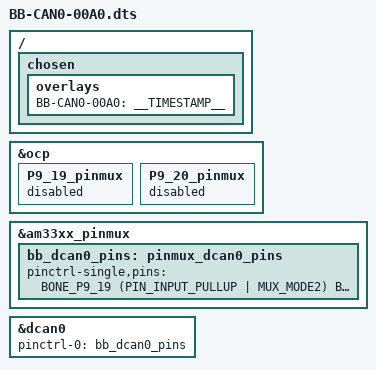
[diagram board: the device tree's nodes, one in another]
/*
 * Copyright (C) 2015 Robert Nelson <robertcnelson@gmail.com>
 *
 * Virtual cape for CAN0 on connector pins P9.19 P9.20
 *
 * This program is free software; you can redistribute it and/or modify
 * it under the terms of the GNU General Public License version 2 as
 * published by the Free Software Foundation.
 */
/dts-v1/;
/plugin/;

#include <dt-bindings/board/am335x-bbw-bbb-base.h>
#include <dt-bindings/pinctrl/am33xx.h>

/ {
	/*
	 * Helper to show loaded overlays under: /proc/device-tree/chosen/overlays/
	 */
	fragment@0 {
		target-path="/";
		__overlay__ {

			chosen {
				overlays {
					BB-CAN0-00A0 = __TIMESTAMP__;
				};
			};
		};
	};

	/*
	 * Free up the pins used by the cape from the pinmux helpers.
	 */
	fragment@1 {
		target = <&ocp>;
		__overlay__ {
			P9_19_pinmux { status = "disabled"; };	/* P9_19: i2c2_scl.d_can0_rx */
			P9_20_pinmux { status = "disabled"; };	/* P9_20: i2c2_sda.d_can0_tx */
		};
	};

	fragment@2 {
		target = <&am33xx_pinmux>;
		__overlay__ {
			bb_dcan0_pins: pinmux_dcan0_pins {
				pinctrl-single,pins = <
					BONE_P9_19 (PIN_INPUT_PULLUP | MUX_MODE2)	/* P9_19: i2c2_scl.d_can0_rx */
					BONE_P9_20 (PIN_OUTPUT_PULLUP | MUX_MODE2)	/* P9_20: i2c2_sda.d_can0_tx */
				>;
			};
		};
	};

	fragment@3 {
		target = <&dcan0>;
		__overlay__ {
			status = "okay";
			pinctrl-names = "default";
			pinctrl-0 = <&bb_dcan0_pins>;
		};
	};
};
